# ATSAMA5D27 register map
Vendor: Microchip Technology Inc.; File version: 1.0
CPU: CA5 r0p1, little endian, no MPU, no FPU, 4 interrupt priority bits
Address unit: 32 bits
Registers are 32-bit, read-write, reset 0x0 unless marked. A register's access mark holds for its fields unless they carry their own. Offsets are from the block's base; [hi:lo] are bit positions; {n}, {i} and the like mark numbered series.

## AES — Advanced Encryption Standard
Base 0xF002C000
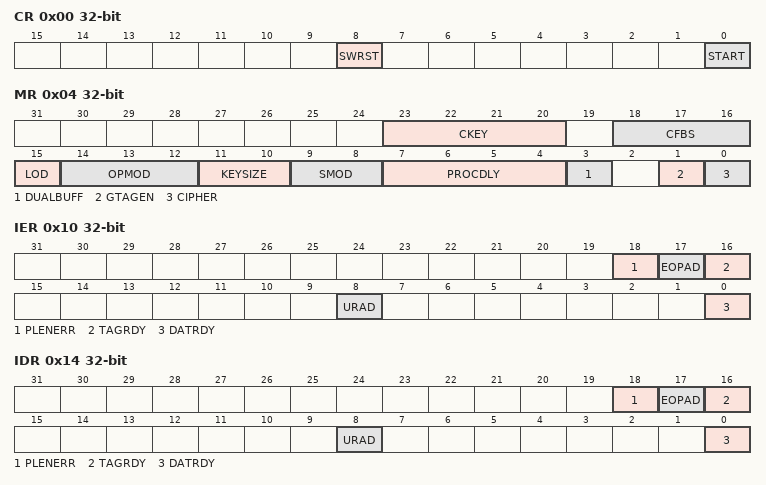
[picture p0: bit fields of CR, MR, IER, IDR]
0x00 CR wo — Control Register
  [8] SWRST rw — Software Reset
  [0] START rw — Start Processing
0x04 MR — Mode Register
  [23:20] CKEY — Key
    14=PASSWD (This field must be written with 0xE the first time AES_MR is programmed. For subsequent programming of AES_MR, any value can be written, including that of 0xE.Always reads as 0.)
  [18:16] CFBS — Cipher Feedback Data Size
    0=SIZE_128BIT (128-bit); 1=SIZE_64BIT (64-bit); 2=SIZE_32BIT (32-bit); 3=SIZE_16BIT (16-bit); 4=SIZE_8BIT (8-bit)
  [15] LOD — Last Output Data Mode
  [14:12] OPMOD — Operating Mode
    0=ECB (ECB: Electronic Codebook mode); 1=CBC (CBC: Cipher Block Chaining mode); 2=OFB (OFB: Output Feedback mode); 3=CFB (CFB: Cipher Feedback mode); 4=CTR (CTR: Counter mode (16-bit internal counter)); 5=GCM (GCM: Galois/Counter mode); 6=XTS (XTS: XEX-based tweaked-codebook mode)
  [11:10] KEYSIZE
    0=AES128 (AES Key Size is 128 bits); 1=AES192 (AES Key Size is 192 bits); 2=AES256 (AES Key Size is 256 bits)
  [9:8] SMOD — Start Mode
    0=MANUAL_START (Manual Mode); 1=AUTO_START (Auto Mode); 2=IDATAR0_START (AES_IDATAR0 access only Auto Mode (DMA))
  [7:4] PROCDLY — Processing Delay
  [3] DUALBUFF — Dual Input Buffer
    0=INACTIVE (AES_IDATARx cannot be written during processing of previous block.); 1=ACTIVE (AES_IDATARx can be written during processing of previous block when SMOD = 2. It speeds up the overall runtime of large files.)
  [1] GTAGEN — GCM Automatic Tag Generation Enable
  [0] CIPHER — Processing Mode
0x10 IER wo — Interrupt Enable Register
  [18] PLENERR rw — Padding Length Error Interrupt Enable
  [17] EOPAD rw — End of Padding Interrupt Enable
  [16] TAGRDY rw — GCM Tag Ready Interrupt Enable
  [8] URAD rw — Unspecified Register Access Detection Interrupt Enable
  [0] DATRDY rw — Data Ready Interrupt Enable
0x14 IDR wo — Interrupt Disable Register
  [18] PLENERR rw — Padding Length Error Interrupt Disable
  [17] EOPAD rw — End of Padding Interrupt Disable
  [16] TAGRDY rw — GCM Tag Ready Interrupt Disable
  [8] URAD rw — Unspecified Register Access Detection Interrupt Disable
  [0] DATRDY rw — Data Ready Interrupt Disable
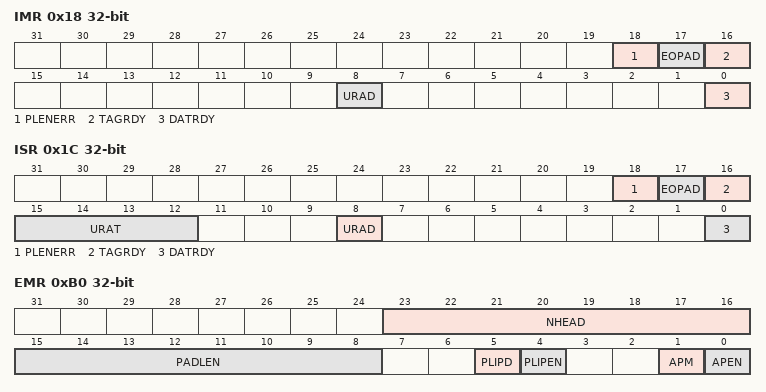
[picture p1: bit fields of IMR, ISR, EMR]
0x18 IMR ro — Interrupt Mask Register
  [18] PLENERR rw — Padding Length Error Interrupt Mask
  [17] EOPAD rw — End of Padding Interrupt Mask
  [16] TAGRDY rw — GCM Tag Ready Interrupt Mask
  [8] URAD rw — Unspecified Register Access Detection Interrupt Mask
  [0] DATRDY rw — Data Ready Interrupt Mask
0x1C ISR ro — Interrupt Status Register
  [18] PLENERR rw — Padding Length Error
  [17] EOPAD rw — End of Padding
  [16] TAGRDY rw — GCM Tag Ready
  [15:12] URAT rw — Unspecified Register Access (cleared by writing SWRST in AES_CR)
    0=IDR_WR_PROCESSING (Input Data register written during the data processing when SMOD = 2 mode.); 1=ODR_RD_PROCESSING (Output Data register read during the data processing.); 2=MR_WR_PROCESSING (Mode register written during the data processing.); 3=ODR_RD_SUBKGEN (Output Data register read during the sub-keys generation.); 4=MR_WR_SUBKGEN (Mode register written during the sub-keys generation.); 5=WOR_RD_ACCESS (Write-only register read access.)
  [8] URAD rw — Unspecified Register Access Detection Status (cleared by writing SWRST in AES_CR)
  [0] DATRDY rw — Data Ready (cleared by setting bit START or bit SWRST in AES_CR or by reading AES_ODATARx)
{0x20+4i} KEYWR{i} wo (i=0..7) — Key Word Register {i}
  [31:0] KEYW rw — Key Word
{0x40+4i} IDATAR{i} wo (i=0..3) — Input Data Register {i}
  [31:0] IDATA rw — Input Data Word
{0x50+4i} ODATAR{i} ro (i=0..3) — Output Data Register {i}
  [31:0] ODATA rw — Output Data
{0x60+4i} IVR{i} wo (i=0..3) — Initialization Vector Register {i}
  [31:0] IV rw — Initialization Vector
0x70 AADLENR — Additional Authenticated Data Length Register
  [31:0] AADLEN — Additional Authenticated Data Length
0x74 CLENR — Plaintext/Ciphertext Length Register
  [31:0] CLEN — Plaintext/Ciphertext Length
0x78 GHASHR — GCM Intermediate Hash Word Register
  [31:0] GHASH — Intermediate GCM Hash Word x
0x88 TAGR ro — GCM Authentication Tag Word Register
  [31:0] TAG rw — GCM Authentication Tag x
0x98 CTRR ro — GCM Encryption Counter Value Register
  [31:0] CTR rw — GCM Encryption Counter
0x9C GCMHR — GCM H Word Register
  [31:0] H — GCM H Word x
0xB0 EMR — Extended Mode Register
  [23:16] NHEAD — IPSEC Next Header
  [15:8] PADLEN — Auto Padding Length
  [5] PLIPD — Protocol Layer Improved Performance Decipher
  [4] PLIPEN — Protocol Layer Improved Performance Enable
  [1] APM — Auto Padding Mode
  [0] APEN — Auto Padding Enable
0xB4 BCNT — Byte Counter Register
  [31:0] BCNT — Auto Padding Byte Counter
0xC0 TWR — Tweak Word Register
  [31:0] TWEAK — Tweak Word x
0xD0 ALPHAR wo — Alpha Word Register
  [31:0] ALPHA rw — Alpha Word x
